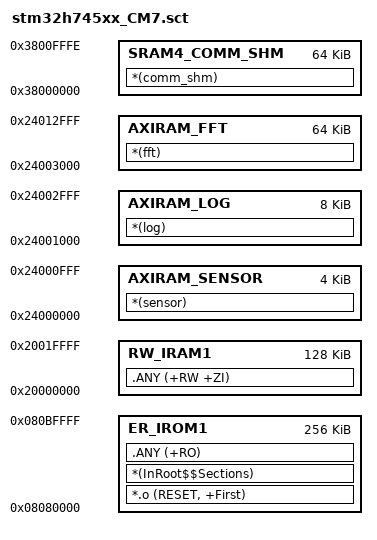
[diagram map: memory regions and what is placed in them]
LR_IROM1 0x08080000 0x00040000 {
        ER_IROM1 0x08080000 0x00040000 {
                *.o (RESET, +First)
                *(InRoot$$Sections)
                .ANY (+RO)
        }

        RW_IRAM1 0x20000000 0x00020000 {
                .ANY (+RW +ZI)
        }

        AXIRAM_SENSOR 0x24000000 0x00001000 {
                *(sensor)
        }

        AXIRAM_LOG 0x24001000 0x00002000 {
                *(log)
        }

        AXIRAM_FFT 0x24003000 0x00010000 {
                *(fft)
        }

        SRAM4_COMM_SHM 0x38000000 0x0000FFFF {
                *(comm_shm)
        }
}
